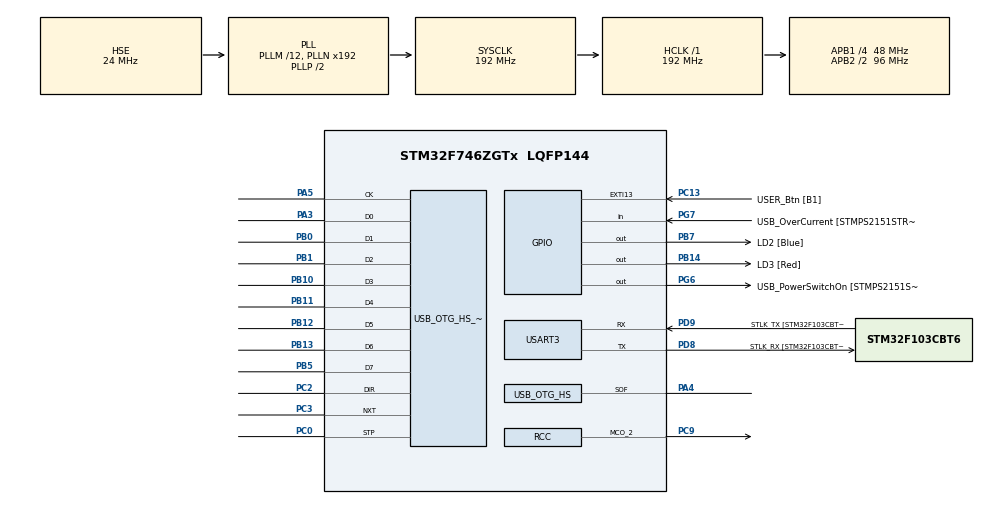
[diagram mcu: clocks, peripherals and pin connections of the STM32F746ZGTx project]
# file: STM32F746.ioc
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DMA2D.AlphaModeForeground=DMA2D_NO_MODIF_ALPHA
DMA2D.ColorMode=DMA2D_OUTPUT_RGB565
DMA2D.InputColorModeBackground=DMA2D_INPUT_RGB565
DMA2D.InputColorModeForeground=DMA2D_INPUT_RGB565
DMA2D.Mode=DMA2D_M2M_BLEND
Mcu.Family=STM32F7
Mcu.Name=STM32F746ZGTx
Mcu.Package=LQFP144
NVIC.DMA2D_IRQn=true\:0\:0\:false\:false\:true\:true\:true
NVIC.OTG_HS_EP1_IN_IRQn=true\:0\:0\:false\:false\:true\:true\:true
NVIC.OTG_HS_EP1_OUT_IRQn=true\:0\:0\:false\:false\:true\:true\:true
NVIC.OTG_HS_IRQn=true\:0\:0\:false\:false\:true\:false\:true
NVIC.PriorityGroup=NVIC_PRIORITYGROUP_4
PA13.GPIO_Label=TMS
PA13.Mode=Serial_Wire
PA13.Signal=SYS_JTMS-SWDIO
PA14.GPIO_Label=TCK
PA14.Mode=Serial_Wire
PA14.Signal=SYS_JTCK-SWCLK
PA3.Mode=Device_HS
PA3.Signal=USB_OTG_HS_ULPI_D0
PA4.Mode=Activate_SOF_FS
PA4.Signal=USB_OTG_HS_SOF
PA5.Mode=Device_HS
PA5.Signal=USB_OTG_HS_ULPI_CK
PB0.Mode=Device_HS
PB0.Signal=USB_OTG_HS_ULPI_D1
PB1.Mode=Device_HS
PB1.Signal=USB_OTG_HS_ULPI_D2
PB10.Mode=Device_HS
PB10.Signal=USB_OTG_HS_ULPI_D3
PB11.Mode=Device_HS
PB11.Signal=USB_OTG_HS_ULPI_D4
PB12.Mode=Device_HS
PB12.Signal=USB_OTG_HS_ULPI_D5
PB13.Mode=Device_HS
PB13.Signal=USB_OTG_HS_ULPI_D6
PB14.GPIO_Label=LD3 [Red]
PB14.Signal=GPIO_Output
PB3.GPIO_Label=SW0
PB3.Signal=SYS_JTDO-SWO
PB5.Mode=Device_HS
PB5.Signal=USB_OTG_HS_ULPI_D7
PB7.GPIO_Label=LD2 [Blue]
PB7.Signal=GPIO_Output
PC0.Mode=Device_HS
PC0.Signal=USB_OTG_HS_ULPI_STP
PC13.GPIO_Label=USER_Btn [B1]
PC13.Signal=GPXTI13
PC2.Mode=Device_HS
PC2.Signal=USB_OTG_HS_ULPI_DIR
PC3.Mode=Device_HS
PC3.Signal=USB_OTG_HS_ULPI_NXT
PC9.Mode=Clock-out-2
PC9.Signal=RCC_MCO_2
PD8.GPIO_Label=STLK_RX [STM32F103CBT6_PA3]
PD8.Mode=Asynchronous
PD8.Signal=USART3_TX
PD9.GPIO_Label=STLK_TX [STM32F103CBT6_PA2]
PD9.Mode=Asynchronous
PD9.Signal=USART3_RX
PG6.GPIO_Label=USB_PowerSwitchOn [STMPS2151STR_EN]
PG6.Signal=GPIO_Output
PG7.GPIO_Label=USB_OverCurrent [STMPS2151STR_FAULT]
PG7.Signal=GPIO_Input
PH0/OSC_IN.GPIO_Label=MCO [STM32F103CBT6_PA8]
PH0/OSC_IN.Mode=HSE-External-Oscillator
PH0/OSC_IN.Signal=RCC_OSC_IN
PH1/OSC_OUT.Mode=HSE-External-Oscillator
PH1/OSC_OUT.Signal=RCC_OSC_OUT
ProjectManager.HeapSize=0x800
ProjectManager.StackSize=0x800
ProjectManager.TargetToolchain=MDK-ARM V5.32
RCC.48MHZClocksFreq_Value=24000000
RCC.AHBFreq_Value=192000000
RCC.APB1CLKDivider=RCC_HCLK_DIV4
RCC.APB1Freq_Value=48000000
RCC.APB1TimFreq_Value=96000000
RCC.APB2CLKDivider=RCC_HCLK_DIV2
RCC.APB2Freq_Value=96000000
RCC.APB2TimFreq_Value=192000000
RCC.CortexFreq_Value=192000000
RCC.HCLKFreq_Value=192000000
RCC.HSE_Timout=500
RCC.HSE_VALUE=24000000
RCC.HSI_VALUE=16000000
RCC.LSE_VALUE=32768
RCC.PLLM=12
RCC.PLLMUL=RCC_PLL_MUL9
RCC.PLLQ=3
RCC.PLLSourceVirtual=RCC_PLLSOURCE_HSE
RCC.PRESCALERUSB=RCC_USBCLKSOURCE_PLL_DIV1_5
RCC.RCC_MCO2Source=RCC_MCO2SOURCE_HSE
RCC.SYSCLKFreq_VALUE=192000000
RCC.SYSCLKSource=RCC_SYSCLKSOURCE_PLLCLK
RCC.SYSCLKSourceVirtual=RCC_SYSCLKSOURCE_PLLCLK
RCC.USBFreq_Value=128000000
RCC.VCOOutputFreq_Value=384000000
USART3.VirtualMode-Asynchronous=VM_ASYNC
USB_DEVICE.CLASS_NAME_HS=CDC
USB_DEVICE.VirtualMode-CDC_HS=Cdc
USB_DEVICE.VirtualModeHS=Cdc_HS
USB_OTG_HS.Sof_enable-Device_HS=ENABLE
USB_OTG_HS.VirtualMode-Device_HS=Device_HS
USB_OTG_HS.dma_enable-Device_HS=DISABLE
VP_DMA2D_VS_DMA2D.Mode=DMA2D_Activate
VP_USB_DEVICE_VS_USB_DEVICE_CDC_HS.Mode=CDC_HS
board=NUCLEO-F746ZG

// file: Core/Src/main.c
/* USER CODE BEGIN Header */
/**
  ******************************************************************************
  * @file           : main.c
  * @brief          : Main program body
  ******************************************************************************
  * @attention
  *
  * Copyright (c) 2022 STMicroelectronics.
  * All rights reserved.
  *
  * This software is licensed under terms that can be found in the LICENSE file
  * in the root directory of this software component.
  * If no LICENSE file comes with this software, it is provided AS-IS.
  *
  ******************************************************************************
  */
/* USER CODE END Header */
#include "main.h"
#include "usb_device.h"

/* USER CODE BEGIN Includes */
#include "usbd_uvc_if.h"

/* USER CODE END Includes */

DMA2D_HandleTypeDef hdma2d;

UART_HandleTypeDef huart3;

void SystemClock_Config(void);
static void MX_GPIO_Init(void);
static void MX_USART3_UART_Init(void);
static void MX_DMA2D_Init(void);

int main(void)
{

  /* MCU Configuration--------------------------------------------------------*/

  /* Reset of all peripherals, Initializes the Flash interface and the Systick. */
  HAL_Init();

  /* Configure the system clock */
  SystemClock_Config();

  /* Initialize all configured peripherals */
  MX_GPIO_Init();
  MX_USART3_UART_Init();
  MX_USB_DEVICE_Init();
  MX_DMA2D_Init();

  /* Infinite loop */
  /* USER CODE BEGIN WHILE */

	int count = 0;
	while (1)
  {
		count++;

    Camera_FillRect(0x0000,0, 0, 447, 319);
    Camera_FillRect(0xFFFFFFFF,count%300, 0, 100, 100);

    /* USER CODE END WHILE */

  }
}

void SystemClock_Config(void)
{
  RCC_OscInitTypeDef RCC_OscInitStruct = {0};
  RCC_ClkInitTypeDef RCC_ClkInitStruct = {0};

  /** Configure the main internal regulator output voltage
  */
  __HAL_RCC_PWR_CLK_ENABLE();
  __HAL_PWR_VOLTAGESCALING_CONFIG(PWR_REGULATOR_VOLTAGE_SCALE1);
  /** Initializes the RCC Oscillators according to the specified parameters
  * in the RCC_OscInitTypeDef structure.
  */
  RCC_OscInitStruct.OscillatorType = RCC_OSCILLATORTYPE_HSE;
  RCC_OscInitStruct.HSEState = RCC_HSE_ON;
  RCC_OscInitStruct.PLL.PLLState = RCC_PLL_ON;
  RCC_OscInitStruct.PLL.PLLSource = RCC_PLLSOURCE_HSE;
  RCC_OscInitStruct.PLL.PLLM = 12;
  RCC_OscInitStruct.PLL.PLLN = 192;
  RCC_OscInitStruct.PLL.PLLP = RCC_PLLP_DIV2;
  RCC_OscInitStruct.PLL.PLLQ = 3;
  if (HAL_RCC_OscConfig(&RCC_OscInitStruct) != HAL_OK)
  {
    Error_Handler();
  }
  /** Activate the Over-Drive mode
  */
  if (HAL_PWREx_EnableOverDrive() != HAL_OK)
  {
    Error_Handler();
  }
  /** Initializes the CPU, AHB and APB buses clocks
  */
  RCC_ClkInitStruct.ClockType = RCC_CLOCKTYPE_HCLK|RCC_CLOCKTYPE_SYSCLK
                              |RCC_CLOCKTYPE_PCLK1|RCC_CLOCKTYPE_PCLK2;
  RCC_ClkInitStruct.SYSCLKSource = RCC_SYSCLKSOURCE_PLLCLK;
  RCC_ClkInitStruct.AHBCLKDivider = RCC_SYSCLK_DIV1;
  RCC_ClkInitStruct.APB1CLKDivider = RCC_HCLK_DIV4;
  RCC_ClkInitStruct.APB2CLKDivider = RCC_HCLK_DIV2;

  if (HAL_RCC_ClockConfig(&RCC_ClkInitStruct, FLASH_LATENCY_6) != HAL_OK)
  {
    Error_Handler();
  }
  HAL_RCC_MCOConfig(RCC_MCO2, RCC_MCO2SOURCE_HSE, RCC_MCODIV_1);
}

static void MX_DMA2D_Init(void)
{

  hdma2d.Instance = DMA2D;
  hdma2d.Init.Mode = DMA2D_M2M_BLEND;
  hdma2d.Init.ColorMode = DMA2D_OUTPUT_RGB565;
  hdma2d.Init.OutputOffset = 0;
  hdma2d.LayerCfg[1].InputOffset = 0;
  hdma2d.LayerCfg[1].InputColorMode = DMA2D_INPUT_RGB565;
  hdma2d.LayerCfg[1].AlphaMode = DMA2D_NO_MODIF_ALPHA;
  hdma2d.LayerCfg[1].InputAlpha = 0;
  hdma2d.LayerCfg[0].InputOffset = 0;
  hdma2d.LayerCfg[0].InputColorMode = DMA2D_INPUT_RGB565;
  hdma2d.LayerCfg[0].AlphaMode = DMA2D_NO_MODIF_ALPHA;
  hdma2d.LayerCfg[0].InputAlpha = 0;
  //hdma2d.LayerCfg[0].AlphaInverted = DMA2D_REGULAR_ALPHA;
  //hdma2d.LayerCfg[0].RedBlueSwap = DMA2D_RB_REGULAR;
  if (HAL_DMA2D_Init(&hdma2d) != HAL_OK)
  {
    Error_Handler();
  }
  if (HAL_DMA2D_ConfigLayer(&hdma2d, 0) != HAL_OK)
  {
    Error_Handler();
  }
  if (HAL_DMA2D_ConfigLayer(&hdma2d, 1) != HAL_OK)
  {
    Error_Handler();
  }

}

static void MX_USART3_UART_Init(void)
{

  huart3.Instance = USART3;
  huart3.Init.BaudRate = 115200;
  huart3.Init.WordLength = UART_WORDLENGTH_8B;
  huart3.Init.StopBits = UART_STOPBITS_1;
  huart3.Init.Parity = UART_PARITY_NONE;
  huart3.Init.Mode = UART_MODE_TX_RX;
  huart3.Init.HwFlowCtl = UART_HWCONTROL_NONE;
  huart3.Init.OverSampling = UART_OVERSAMPLING_16;
  huart3.Init.OneBitSampling = UART_ONE_BIT_SAMPLE_DISABLE;
  huart3.AdvancedInit.AdvFeatureInit = UART_ADVFEATURE_NO_INIT;
  if (HAL_UART_Init(&huart3) != HAL_OK)
  {
    Error_Handler();
  }

}

static void MX_GPIO_Init(void)
{
  GPIO_InitTypeDef GPIO_InitStruct = {0};

  /* GPIO Ports Clock Enable */
  __HAL_RCC_GPIOC_CLK_ENABLE();
  __HAL_RCC_GPIOH_CLK_ENABLE();
  __HAL_RCC_GPIOA_CLK_ENABLE();
  __HAL_RCC_GPIOB_CLK_ENABLE();
  __HAL_RCC_GPIOD_CLK_ENABLE();
  __HAL_RCC_GPIOG_CLK_ENABLE();

  /*Configure GPIO pin Output Level */
  HAL_GPIO_WritePin(GPIOB, LD3_Pin|LD2_Pin, GPIO_PIN_RESET);

  /*Configure GPIO pin Output Level */
  HAL_GPIO_WritePin(USB_PowerSwitchOn_GPIO_Port, USB_PowerSwitchOn_Pin, GPIO_PIN_RESET);

  /*Configure GPIO pin : USER_Btn_Pin */
  GPIO_InitStruct.Pin = USER_Btn_Pin;
  GPIO_InitStruct.Mode = GPIO_MODE_IT_RISING;
  GPIO_InitStruct.Pull = GPIO_NOPULL;
  HAL_GPIO_Init(USER_Btn_GPIO_Port, &GPIO_InitStruct);

  /*Configure GPIO pins : LD3_Pin LD2_Pin */
  GPIO_InitStruct.Pin = LD3_Pin|LD2_Pin;
  GPIO_InitStruct.Mode = GPIO_MODE_OUTPUT_PP;
  GPIO_InitStruct.Pull = GPIO_NOPULL;
  GPIO_InitStruct.Speed = GPIO_SPEED_FREQ_LOW;
  HAL_GPIO_Init(GPIOB, &GPIO_InitStruct);

  /*Configure GPIO pin : USB_PowerSwitchOn_Pin */
  GPIO_InitStruct.Pin = USB_PowerSwitchOn_Pin;
  GPIO_InitStruct.Mode = GPIO_MODE_OUTPUT_PP;
  GPIO_InitStruct.Pull = GPIO_NOPULL;
  GPIO_InitStruct.Speed = GPIO_SPEED_FREQ_LOW;
  HAL_GPIO_Init(USB_PowerSwitchOn_GPIO_Port, &GPIO_InitStruct);

  /*Configure GPIO pin : USB_OverCurrent_Pin */
  GPIO_InitStruct.Pin = USB_OverCurrent_Pin;
  GPIO_InitStruct.Mode = GPIO_MODE_INPUT;
  GPIO_InitStruct.Pull = GPIO_NOPULL;
  HAL_GPIO_Init(USB_OverCurrent_GPIO_Port, &GPIO_InitStruct);

  /*Configure GPIO pin : PC9 */
  GPIO_InitStruct.Pin = GPIO_PIN_9;
  GPIO_InitStruct.Mode = GPIO_MODE_AF_PP;
  GPIO_InitStruct.Pull = GPIO_NOPULL;
  GPIO_InitStruct.Speed = GPIO_SPEED_FREQ_LOW;
  GPIO_InitStruct.Alternate = GPIO_AF0_MCO;
  HAL_GPIO_Init(GPIOC, &GPIO_InitStruct);

}

void Error_Handler(void)
{
  __disable_irq();
  while (1)
  {
  }
}
